# AT32F403A register map
Vendor: Keil; Series: AT32F403A; File version: 1.0
CPU: CM4 r0p1, little endian, no MPU, FPU, 4 interrupt priority bits
Registers are 32-bit, read-write, reset 0x0 unless marked. A register's access mark holds for its fields unless they carry their own. Offsets are from the block's base; [hi:lo] are bit positions; lines under a group give offsets from that group; {n}, {i} and the like mark numbered series; 'fields as' and 'values as' point back to an identical list.

## FLASH — Flash memory controler
Base 0x40022000
0x00 PSR reset 0x30 — Performance selection register
0x04 Bank{i} (i=1..3; step 0x40) group — Bank {i} registers
  0x00 UNLOCK wo — Bank unlock register
    [31:0] UKVAL — Unlock key value
      0x45670123=Key1 (Unlock key 1); 0xCDEF89AB=Key2 (Unlock key 2)
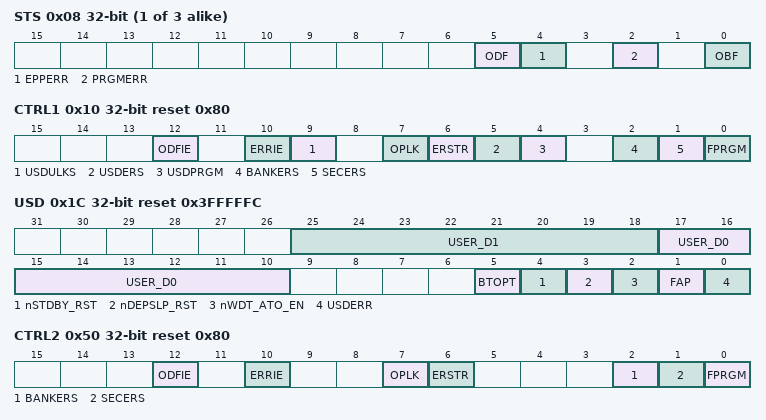
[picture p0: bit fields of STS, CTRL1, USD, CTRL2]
  0x08 STS — Bank status register
    [5] ODF write-1-clears — Operate done flag
      0=NotSet (Flash operation done flag not set); 1=Done (Flash/erase operation done)
    [4] EPPERR write-1-clears — Erase/program protection error
      0=NoError (No erase/program error); 1=Error (Erase/program error occurred)
    [2] PRGMERR write-1-clears — program error
      0=NoError (No program error); 1=Error (Program error occurred)
    [0] OBF ro — Operate busy flag
      0=Idle (Flash is idle); 1=Busy (Flash operation is in progress)
  0x10 ADDR wo — Bank address register
0x08 USD_UNLOCK wo
  [31:0] USD_UKVAL — User system data Unlock key value
    values as Bank{i}.UNLOCK.UKVAL
0x10 CTRL1 reset 0x80 — Control register
  [12] ODFIE — Operation done flag interrupt enable
    0=Disabled (Operation done interrupt disabled); 1=Enabled (Operation done interrupt enabled)
  [10] ERRIE — Error interrupt enable
    0=Disabled (Error interrupt disabled); 1=Enabled (Error interrupt enabled)
  [9] USDULKS — User system data unlock success
  [7] OPLK — Operation lock
    0=Unlocked (Flash operations unlocked); 1=Locked (Flash operations locked)
  [6] ERSTR — Erasing start
    on read: 0=NotStarted (Erase operation not started); 1=Started (Erase operation is in progress) | on write: 0=NoStart (Erase operation not started); 1=Start of erase operation
  [5] USDERS — User system data erase
  [4] USDPRGM — User system data program
  [2] BANKERS — Bank erase
  [1] SECERS — Sector erase
    0=Not sector erase operation; 1=SectorErase (Erase operation is sector erase operation)
  [0] FPRGM — Flash program
    on read: 0=NotStarted (Flash program not started); 1=Started (Flash program is in progress) | on write: 0=NoStart (Flash program not started); 1=Start of flash program operation
0x1C USD ro reset 0x3FFFFFC — User system data register
  [8n+17:8n+10] USER_D{n} (n=0..1) — User data byte {n}
  [5] BTOPT — boot option
  [4] nSTDBY_RST — Standby reset
  [3] nDEPSLP_RST — Deepsleep reset
  [2] nWDT_ATO_EN — WDT auto enable
  [1] FAP — FLASH access protection
    0=Disabled (Flash access protection disabled); 1=Enabled (Flash access protection enabled)
  [0] USDERR — User system data error
    0=NoError (No user system data error); 1=Error (User system data error occurred. Some byte does not match it's inverse code. They both will be forced to 0xFF when read)
0x20 EPPS ro reset 0xFFFFFFFF — Erase/program protection status register
0x50 CTRL2 reset 0x80 — Control 2 register
  [12] ODFIE — Operation done flag interrupt enable
    values as CTRL1.ODFIE
  [10] ERRIE — Error interrupt enable
    values as CTRL1.ERRIE
  [7] OPLK — Operation lock
    values as CTRL1.OPLK
  [6] ERSTR — Erasing start
    values as CTRL1.ERSTR
  [2] BANKERS — Bank erase
  [1] SECERS — Sector erase
    values as CTRL1.SECERS
  [0] FPRGM — Flash program
    values as CTRL1.FPRGM
0x88 SELECT wo
  [31:0] SELECT — spim type selection
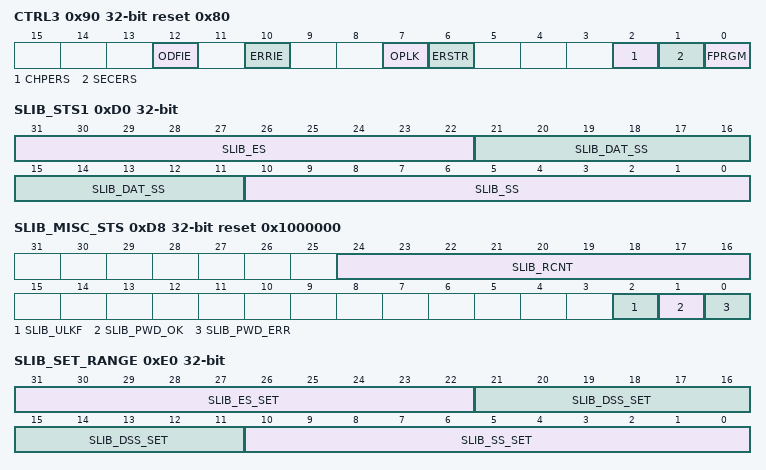
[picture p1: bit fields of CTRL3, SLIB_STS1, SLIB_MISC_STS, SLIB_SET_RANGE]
0x90 CTRL3 reset 0x80 — Control 3 register
  [12] ODFIE — Operation done flag interrupt enable
    values as CTRL1.ODFIE
  [10] ERRIE — Error interrupt enable
    values as CTRL1.ERRIE
  [7] OPLK — Operation lock
    values as CTRL1.OPLK
  [6] ERSTR — Erasing start
    values as CTRL1.ERSTR
  [2] CHPERS — Chip erase
  [1] SECERS — Sector erase
    values as CTRL1.SECERS
  [0] FPRGM — Flash program
    values as CTRL1.FPRGM
0x98 DA wo — Spim decryption address
  [31:0] FDA — Flash decryption address
0xCC SLIB_STS0 — sLib status 0 register
  [3] SLIB_ENF ro — sLib enabled flag
0xD0 SLIB_STS1 — sLib status 1 register
  [31:22] SLIB_ES ro — sLib end sector
  [21:11] SLIB_DAT_SS ro — sLib data start sector
  [10:0] SLIB_SS ro — sLib start sector
0xD4 SLIB_PWD_CLR wo — SLIB password clear register
  [31:0] SLIB_PCLR_VAL — sLib password clear value
0xD8 SLIB_MISC_STS reset 0x1000000 — sLib misc status register
  [24:16] SLIB_RCNT ro — sLib remaining count
  [2] SLIB_ULKF ro — sLib unlock flag
  [1] SLIB_PWD_OK ro — sLib password ok
  [0] SLIB_PWD_ERR ro — sLib password error
0xDC SLIB_SET_PWD wo — sLib password setting register
  [31:0] SLIB_PSET_VAL — sLib password setting val
0xE0 SLIB_SET_RANGE wo — Configure sLib range register
  [31:22] SLIB_ES_SET — sLib end sector setting,valid input: 0~511
  [21:11] SLIB_DSS_SET — sLib data start sector setting,valid input: 0~511, 0 means no data area
  [10:0] SLIB_SS_SET — sLib start sector setting,valid input: 0~511
0xF0 SLIB_UNLOCK wo
  [31:0] SLIB_UKVAL — sLib unlock key value
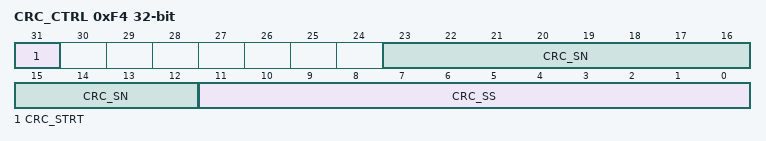
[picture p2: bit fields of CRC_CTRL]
0xF4 CRC_CTRL wo — CRC controler register
  [31] CRC_STRT — CRC start
  [23:12] CRC_SN — CRC sector numbler
  [11:0] CRC_SS — CRC start sector
0xF8 CRC_CHKR ro — CRC check result register
  [31:0] CRC_CHKR — CRC check result
